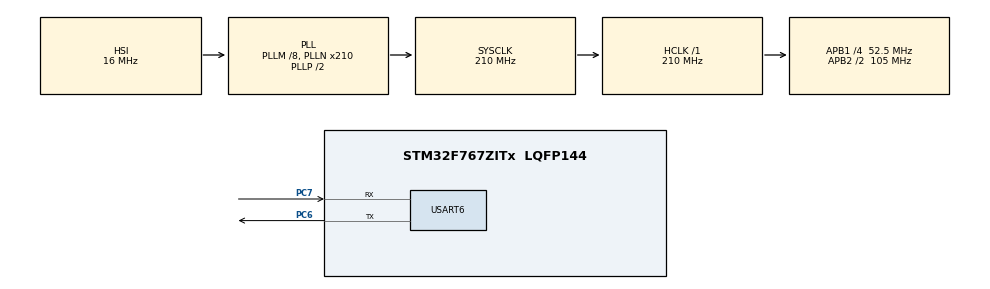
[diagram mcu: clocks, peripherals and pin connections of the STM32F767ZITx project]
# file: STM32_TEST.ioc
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FREERTOS.Tasks01=defaultTask,0,256,StartDefaultTask,Default,NULL,Dynamic,NULL,NULL
Mcu.Family=STM32F7
Mcu.Name=STM32F767ZITx
Mcu.Package=LQFP144
NVIC.PriorityGroup=NVIC_PRIORITYGROUP_4
NVIC.TIM2_IRQn=true\:0\:0\:false\:false\:true\:false\:false\:true
NVIC.TimeBase=TIM2_IRQn
NVIC.TimeBaseIP=TIM2
PC6.Mode=Asynchronous
PC6.Signal=USART6_TX
PC7.Mode=Asynchronous
PC7.Signal=USART6_RX
ProjectManager.HeapSize=0x200
ProjectManager.StackSize=0x400
ProjectManager.TargetToolchain=STM32CubeIDE
RCC.48MHZClocksFreq_Value=24000000
RCC.AHBFreq_Value=210000000
RCC.APB1CLKDivider=RCC_HCLK_DIV4
RCC.APB1Freq_Value=52500000
RCC.APB1TimFreq_Value=105000000
RCC.APB2CLKDivider=RCC_HCLK_DIV2
RCC.APB2Freq_Value=105000000
RCC.APB2TimFreq_Value=210000000
RCC.CortexFreq_Value=210000000
RCC.HCLKFreq_Value=210000000
RCC.HSE_VALUE=16000000
RCC.HSI_VALUE=16000000
RCC.LSE_VALUE=32768
RCC.PLLM=8
RCC.PLLMUL=RCC_PLL_MUL9
RCC.PLLN=210
RCC.PRESCALERUSB=RCC_USBCLKSOURCE_PLL_DIV1_5
RCC.SYSCLKFreq_VALUE=210000000
RCC.SYSCLKSource=RCC_SYSCLKSOURCE_PLLCLK
RCC.SYSCLKSourceVirtual=RCC_SYSCLKSOURCE_PLLCLK
RCC.USBFreq_Value=210000000
RCC.VCOOutputFreq_Value=420000000
USART6.VirtualMode-Asynchronous=VM_ASYNC
VP_FREERTOS_VS_CMSIS_V1.Mode=CMSIS_V1
VP_SYS_VS_tim2.Mode=TIM2
board=NUCLEO-F767ZI

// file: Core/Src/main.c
/* USER CODE BEGIN Header */
/**
  ******************************************************************************
  * @file           : main.c
  * @brief          : Main program body
  ******************************************************************************
  * @attention
  *
  * <h2><center>&copy; Copyright (c) 2020 STMicroelectronics.
  * All rights reserved.</center></h2>
  *
  * This software component is licensed by ST under BSD 3-Clause license,
  * the "License"; You may not use this file except in compliance with the
  * License. You may obtain a copy of the License at:
  *                        opensource.org/licenses/BSD-3-Clause
  *
  ******************************************************************************
  */
/* USER CODE END Header */

#include "main.h"
#include "cmsis_os.h"

/* USER CODE BEGIN Includes */
#include <stdint.h>
#include <stdio.h>
#include "arm_math.h"
#include "arm_nnexamples_cifar10_parameter.h"
#include "arm_nnexamples_cifar10_weights.h"

#include "arm_nnfunctions.h"
#include "arm_nnexamples_cifar10_inputs.h"

#ifdef _RTE_
#include "RTE_Components.h"
#ifdef RTE_Compiler_EventRecorder
#include "EventRecorder.h"
#endif
#endif
/* USER CODE END Includes */

UART_HandleTypeDef huart6;

osThreadId defaultTaskHandle;
/* USER CODE BEGIN PV */
// include the input and weights

static q7_t conv1_wt[CONV1_IM_CH * CONV1_KER_DIM * CONV1_KER_DIM * CONV1_OUT_CH] = CONV1_WT;
static q7_t conv1_bias[CONV1_OUT_CH] = CONV1_BIAS;

static q7_t conv2_wt[CONV2_IM_CH * CONV2_KER_DIM * CONV2_KER_DIM * CONV2_OUT_CH] = CONV2_WT;
static q7_t conv2_bias[CONV2_OUT_CH] = CONV2_BIAS;

static q7_t conv3_wt[CONV3_IM_CH * CONV3_KER_DIM * CONV3_KER_DIM * CONV3_OUT_CH] = CONV3_WT;
static q7_t conv3_bias[CONV3_OUT_CH] = CONV3_BIAS;

static q7_t ip1_wt[IP1_DIM * IP1_OUT] = IP1_WT;
static q7_t ip1_bias[IP1_OUT] = IP1_BIAS;

/* Here the image_data should be the raw uint8 type RGB image in [RGB, RGB, RGB ... RGB] format */
uint8_t   image_data[CONV1_IM_CH * CONV1_IM_DIM * CONV1_IM_DIM] = IMG_DATA;
q7_t      output_data[IP1_OUT];

//vector buffer: max(im2col buffer,average pool buffer, fully connected buffer)
q7_t      col_buffer[2 * 5 * 5 * 32 * 2];

q7_t      scratch_buffer[32 * 32 * 10 * 4];
/* USER CODE END PV */

void SystemClock_Config(void);
static void MX_GPIO_Init(void);
static void MX_USART6_UART_Init(void);
void StartDefaultTask(void const * argument);

/* USER CODE BEGIN 0 */
#ifdef __GNUC__
#define PUTCHAR_PROTOTYPE int __io_putchar(int ch)
#else
#define PUTCHAR_PROTOTYPE int fputc(int ch, FILE *f)
#endif
PUTCHAR_PROTOTYPE
{
		HAL_UART_Transmit(&huart6 , (uint8_t *)&ch, 1, 0xFFFF);
		return ch;
}
/* USER CODE END 0 */

int main(void)
{

  /* MCU Configuration--------------------------------------------------------*/

  /* Reset of all peripherals, Initializes the Flash interface and the Systick. */
  HAL_Init();

  /* Configure the system clock */
  SystemClock_Config();

  /* Initialize all configured peripherals */
  MX_GPIO_Init();
  MX_USART6_UART_Init();
  /* USER CODE BEGIN 2 */
  //SleepMode_Measure();
  /* USER CODE END 2 */

  /* Create the thread(s) */
  /* definition and creation of defaultTask */
  osThreadDef(defaultTask, StartDefaultTask, osPriorityNormal, 0, 256);
  defaultTaskHandle = osThreadCreate(osThread(defaultTask), NULL);

  /* Start scheduler */
  osKernelStart();

  /* We should never get here as control is now taken by the scheduler */
  /* Infinite loop */
  while (1)
  {

  }
}

void SystemClock_Config(void)
{
  RCC_OscInitTypeDef RCC_OscInitStruct = {0};
  RCC_ClkInitTypeDef RCC_ClkInitStruct = {0};
  RCC_PeriphCLKInitTypeDef PeriphClkInitStruct = {0};

  /** Configure the main internal regulator output voltage
  */
  __HAL_RCC_PWR_CLK_ENABLE();
  __HAL_PWR_VOLTAGESCALING_CONFIG(PWR_REGULATOR_VOLTAGE_SCALE1);
  /** Initializes the CPU, AHB and APB busses clocks
  */
  RCC_OscInitStruct.OscillatorType = RCC_OSCILLATORTYPE_HSI;
  RCC_OscInitStruct.HSIState = RCC_HSI_ON;
  RCC_OscInitStruct.HSICalibrationValue = RCC_HSICALIBRATION_DEFAULT;
  RCC_OscInitStruct.PLL.PLLState = RCC_PLL_ON;
  RCC_OscInitStruct.PLL.PLLSource = RCC_PLLSOURCE_HSI;
  RCC_OscInitStruct.PLL.PLLM = 8;
  RCC_OscInitStruct.PLL.PLLN = 210;
  RCC_OscInitStruct.PLL.PLLP = RCC_PLLP_DIV2;
  RCC_OscInitStruct.PLL.PLLQ = 2;
  if (HAL_RCC_OscConfig(&RCC_OscInitStruct) != HAL_OK)
  {
    Error_Handler();
  }
  /** Activate the Over-Drive mode
  */
  if (HAL_PWREx_EnableOverDrive() != HAL_OK)
  {
    Error_Handler();
  }
  /** Initializes the CPU, AHB and APB busses clocks
  */
  RCC_ClkInitStruct.ClockType = RCC_CLOCKTYPE_HCLK|RCC_CLOCKTYPE_SYSCLK
                              |RCC_CLOCKTYPE_PCLK1|RCC_CLOCKTYPE_PCLK2;
  RCC_ClkInitStruct.SYSCLKSource = RCC_SYSCLKSOURCE_PLLCLK;
  RCC_ClkInitStruct.AHBCLKDivider = RCC_SYSCLK_DIV1;
  RCC_ClkInitStruct.APB1CLKDivider = RCC_HCLK_DIV4;
  RCC_ClkInitStruct.APB2CLKDivider = RCC_HCLK_DIV2;

  if (HAL_RCC_ClockConfig(&RCC_ClkInitStruct, FLASH_LATENCY_6) != HAL_OK)
  {
    Error_Handler();
  }
  PeriphClkInitStruct.PeriphClockSelection = RCC_PERIPHCLK_USART6;
  PeriphClkInitStruct.Usart6ClockSelection = RCC_USART6CLKSOURCE_PCLK2;
  if (HAL_RCCEx_PeriphCLKConfig(&PeriphClkInitStruct) != HAL_OK)
  {
    Error_Handler();
  }
}

static void MX_USART6_UART_Init(void)
{

  huart6.Instance = USART6;
  huart6.Init.BaudRate = 115200;
  huart6.Init.WordLength = UART_WORDLENGTH_8B;
  huart6.Init.StopBits = UART_STOPBITS_1;
  huart6.Init.Parity = UART_PARITY_NONE;
  huart6.Init.Mode = UART_MODE_TX_RX;
  huart6.Init.HwFlowCtl = UART_HWCONTROL_NONE;
  huart6.Init.OverSampling = UART_OVERSAMPLING_16;
  huart6.Init.OneBitSampling = UART_ONE_BIT_SAMPLE_DISABLE;
  huart6.AdvancedInit.AdvFeatureInit = UART_ADVFEATURE_NO_INIT;
  if (HAL_UART_Init(&huart6) != HAL_OK)
  {
    Error_Handler();
  }

}

static void MX_GPIO_Init(void)
{

  /* GPIO Ports Clock Enable */
  __HAL_RCC_GPIOC_CLK_ENABLE();

}

/* USER CODE BEGIN 4 */
/**
  * @brief  This function configures the system to enter Sleep mode for
  *         current consumption measurement purpose.
  *         Sleep Mode
  *         ==========
  *            - System Running at PLL (216MHz)
  *            - Flash 5 wait state
  *            - Instruction and Data caches ON
  *            - Prefetch ON
  *            - Code running from Internal FLASH
  *            - Wakeup using EXTI Line (USER Button)
  * @param  None
  * @retval None
  */
void SleepMode_Measure(void)
{

  /* Suspend Tick increment to prevent wakeup by Systick interrupt.
     Otherwise the Systick interrupt will wake up the device within 1ms (HAL time base) */
  HAL_SuspendTick();

  /* Request to enter SLEEP mode */
  HAL_PWR_EnterSLEEPMode(PWR_MAINREGULATOR_ON, PWR_SLEEPENTRY_WFI);

  /* Resume Tick interrupt if disabled prior to sleep mode entry */
  HAL_ResumeTick();

}
/* USER CODE END 4 */

void StartDefaultTask(void const * argument)
{
  /* USER CODE BEGIN 5 */
  /* Infinite loop */
  for(;;)
  {

#ifdef RTE_Compiler_EventRecorder
 EventRecorderInitialize (EventRecordAll, 1);  // initialize and start Event Recorder
 #endif

 //HAL_UART_Transmit(&huart6,"start execution\n",20,1000);//發送串口
 printf("start execution\n");
 /* start the execution */

 q7_t     *img_buffer1 = scratch_buffer;
 q7_t     *img_buffer2 = img_buffer1 + 32 * 32 * 32;

 /* input pre-processing */
 int mean_data[3] = INPUT_MEAN_SHIFT;
 unsigned int scale_data[3] = INPUT_RIGHT_SHIFT;
 for (int i=0;i<32*32*3; i+=3) {
   img_buffer2[i] =   (q7_t)__SSAT( ((((int)image_data[i]   - mean_data[0])<<7) + (0x1<<(scale_data[0]-1)))
                            >> scale_data[0], 8);
   img_buffer2[i+1] = (q7_t)__SSAT( ((((int)image_data[i+1] - mean_data[1])<<7) + (0x1<<(scale_data[1]-1)))
                            >> scale_data[1], 8);
   img_buffer2[i+2] = (q7_t)__SSAT( ((((int)image_data[i+2] - mean_data[2])<<7) + (0x1<<(scale_data[2]-1)))
                            >> scale_data[2], 8);
 }

 // conv1 img_buffer2 -> img_buffer1
 arm_convolve_HWC_q7_RGB(img_buffer2, CONV1_IM_DIM, CONV1_IM_CH, conv1_wt, CONV1_OUT_CH, CONV1_KER_DIM, CONV1_PADDING,
                         CONV1_STRIDE, conv1_bias, CONV1_BIAS_LSHIFT, CONV1_OUT_RSHIFT, img_buffer1, CONV1_OUT_DIM,
                         (q15_t *) col_buffer, NULL);

 arm_relu_q7(img_buffer1, CONV1_OUT_DIM * CONV1_OUT_DIM * CONV1_OUT_CH);

 // pool1 img_buffer1 -> img_buffer2
 arm_maxpool_q7_HWC(img_buffer1, CONV1_OUT_DIM, CONV1_OUT_CH, POOL1_KER_DIM,
                    POOL1_PADDING, POOL1_STRIDE, POOL1_OUT_DIM, NULL, img_buffer2);

 // conv2 img_buffer2 -> img_buffer1
 arm_convolve_HWC_q7_fast(img_buffer2, CONV2_IM_DIM, CONV2_IM_CH, conv2_wt, CONV2_OUT_CH, CONV2_KER_DIM,
                          CONV2_PADDING, CONV2_STRIDE, conv2_bias, CONV2_BIAS_LSHIFT, CONV2_OUT_RSHIFT, img_buffer1,
                          CONV2_OUT_DIM, (q15_t *) col_buffer, NULL);

 arm_relu_q7(img_buffer1, CONV2_OUT_DIM * CONV2_OUT_DIM * CONV2_OUT_CH);

 // pool2 img_buffer1 -> img_buffer2
 arm_maxpool_q7_HWC(img_buffer1, CONV2_OUT_DIM, CONV2_OUT_CH, POOL2_KER_DIM,
                    POOL2_PADDING, POOL2_STRIDE, POOL2_OUT_DIM, col_buffer, img_buffer2);

// conv3 img_buffer2 -> img_buffer1
 arm_convolve_HWC_q7_fast(img_buffer2, CONV3_IM_DIM, CONV3_IM_CH, conv3_wt, CONV3_OUT_CH, CONV3_KER_DIM,
                          CONV3_PADDING, CONV3_STRIDE, conv3_bias, CONV3_BIAS_LSHIFT, CONV3_OUT_RSHIFT, img_buffer1,
                          CONV3_OUT_DIM, (q15_t *) col_buffer, NULL);

 arm_relu_q7(img_buffer1, CONV3_OUT_DIM * CONV3_OUT_DIM * CONV3_OUT_CH);

 // pool3 img_buffer-> img_buffer2
 arm_maxpool_q7_HWC(img_buffer1, CONV3_OUT_DIM, CONV3_OUT_CH, POOL3_KER_DIM,
                    POOL3_PADDING, POOL3_STRIDE, POOL3_OUT_DIM, col_buffer, img_buffer2);

 arm_fully_connected_q7_opt(img_buffer2, ip1_wt, IP1_DIM, IP1_OUT, IP1_BIAS_LSHIFT, IP1_OUT_RSHIFT, ip1_bias,
                            output_data, (q15_t *) img_buffer1);

 arm_softmax_q7(output_data, 10, output_data);

 for (int i = 0; i < 10; i++)
 {
     printf("%d: %d\n", i, output_data[i]);
 }
 uint32_t tick = HAL_GetTick();
 printf("It is a cat\n");
 printf("time is %d\n",tick);
    osDelay(1);
  }
  /* USER CODE END 5 */
}

 /**
  * @brief  Period elapsed callback in non blocking mode
  * @note   This function is called  when TIM2 interrupt took place, inside
  * HAL_TIM_IRQHandler(). It makes a direct call to HAL_IncTick() to increment
  * a global variable "uwTick" used as application time base.
  * @param  htim : TIM handle
  * @retval None
  */
void HAL_TIM_PeriodElapsedCallback(TIM_HandleTypeDef *htim)
{
  if (htim->Instance == TIM2) {
    HAL_IncTick();
  }
}

void Error_Handler(void)
{
}

/************************ (C) COPYRIGHT STMicroelectronics *****END OF FILE****/
